# STM32WLE5_CM4 register map
File version: 1.0
CPU: CM4 r0p1, little endian, MPU, FPU, 4 interrupt priority bits
Registers are 32-bit, read-write, reset 0x0 unless marked. A register's access mark holds for its fields unless they carry their own. Offsets are from the block's base; [hi:lo] are bit positions.

## FLASH
Base 0x58004000
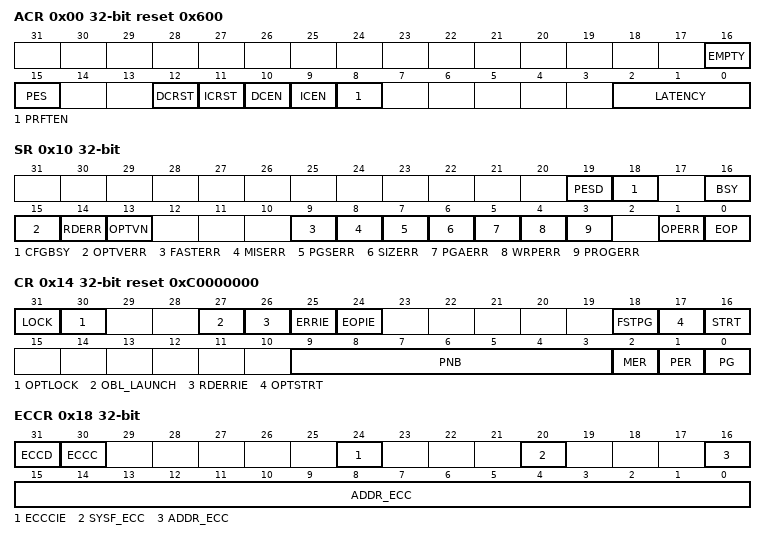
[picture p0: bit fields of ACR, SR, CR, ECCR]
0x00 ACR reset 0x600 — Access control register
  [16] EMPTY — Flash User area empty
  [15] PES — CPU1 programm erase suspend request
  [12] DCRST — Data cache reset
  [11] ICRST — Instruction cache reset
  [10] DCEN — Data cache enable
  [9] ICEN — Instruction cache enable
  [8] PRFTEN — Prefetch enable
  [2:0] LATENCY
0x08 KEYR wo — Flash key register
  [31:0] KEY
0x0C OPTKEYR wo — Option byte key register
  [31:0] OPTKEYR — Option byte key
0x10 SR access per field — Status register
  [19] PESD ro — Programming / erase operation suspended
  [18] CFGBSY ro — Programming or erase configuration busy
  [16] BSY ro — Busy
  [15] OPTVERR rw — Option validity error
  [14] RDERR rw — PCROP read error
  [13] OPTVN ro — User Option OPTIVAL indication
  [9] FASTERR rw — Fast programming error
  [8] MISERR rw — Fast programming data miss error
  [7] PGSERR rw — Programming sequence error
  [6] SIZERR rw — Size error
  [5] PGAERR rw — Programming alignment error
  [4] WRPERR rw — Write protected error
  [3] PROGERR rw — Programming error
  [1] OPERR rw — Operation error
  [0] EOP rw — End of operation
0x14 CR reset 0xC0000000 — Flash control register
  [31] LOCK — FLASH_CR Lock
  [30] OPTLOCK — Options Lock
  [27] OBL_LAUNCH — Force the option byte loading
  [26] RDERRIE — PCROP read error interrupt enable
  [25] ERRIE — Error interrupt enable
  [24] EOPIE — End of operation interrupt enable
  [18] FSTPG — Fast programming
  [17] OPTSTRT — Options modification start
  [16] STRT — Start
  [9:3] PNB — Page number
  [2] MER — Mass erase
  [1] PER — Page erase
  [0] PG — Programming
0x18 ECCR access per field — Flash ECC register
  [31] ECCD rw — ECC detection
  [30] ECCC rw — ECC correction
  [24] ECCCIE rw — ECC correction interrupt enable
  [20] SYSF_ECC ro — System Flash ECC fail
  [16:0] ADDR_ECC ro — ECC fail address
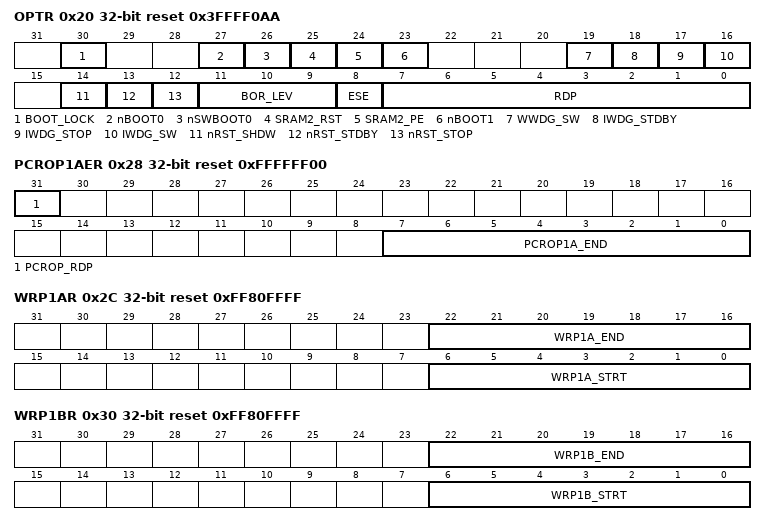
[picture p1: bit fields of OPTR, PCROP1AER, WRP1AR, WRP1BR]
0x20 OPTR reset 0x3FFFF0AA — Flash option register
  [30] BOOT_LOCK — CPU1 CM4 Unique Boot entry enable option bit
  [27] nBOOT0 — nBOOT0 option bit
  [26] nSWBOOT0 — Software BOOT0 selection
  [25] SRAM2_RST — SRAM2 Erase when system reset
  [24] SRAM2_PE — SRAM2 parity check enable
  [23] nBOOT1 — Boot configuration
  [19] WWDG_SW — Window watchdog selection
  [18] IWDG_STDBY — Independent watchdog counter freeze in Standby mode
  [17] IWDG_STOP — Independent watchdog counter freeze in Stop mode
  [16] IWDG_SW — Independent watchdog selection
  [14] nRST_SHDW
  [13] nRST_STDBY
  [12] nRST_STOP
  [11:9] BOR_LEV — BOR reset Level
  [8] ESE — System security enabled flag
  [7:0] RDP — Read protection level
0x24 PCROP1ASR ro reset 0xFFFFFFFF — Flash PCROP zone A Start address register
  [7:0] PCROP1A_STRT — PCROP1A area start offset
0x28 PCROP1AER reset 0xFFFFFF00 — Flash PCROP zone A End address register
  [31] PCROP_RDP — PCROP area preserved when RDP level decreased
  [7:0] PCROP1A_END — PCROP area end offset
0x2C WRP1AR reset 0xFF80FFFF — Flash WRP area A address register
  [22:16] WRP1A_END — Bank 1 WRP first area A end offset
  [6:0] WRP1A_STRT — Bank 1 WRP first area start offset
0x30 WRP1BR reset 0xFF80FFFF — Flash WRP area B address register
  [22:16] WRP1B_END — Bank 1 WRP second area B start offset
  [6:0] WRP1B_STRT — Bank 1 WRP second area B end offset
0x34 PCROP1BSR reset 0xFFFFFFFF — Flash PCROP zone B Start address register
  [7:0] PCROP1B_STRT — Bank 1 WRP second area B end offset
0x38 PCROP1BER reset 0xFFFFFF00 — Flash PCROP zone B End address register
  [7:0] PCROP1B_END — PCROP1B area end offset

## EXTI — External interrupt/event controller
Base 0x58000800
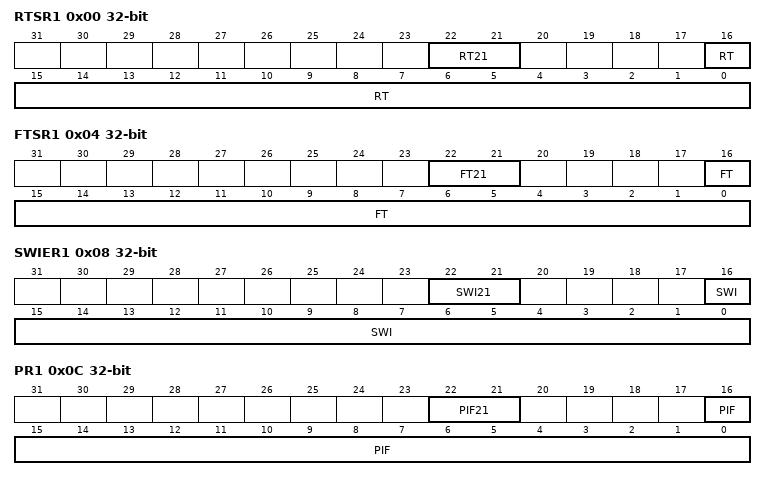
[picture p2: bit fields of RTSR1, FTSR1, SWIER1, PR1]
0x00 RTSR1 — rising trigger selection register
  [22:21] RT21 — Rising trigger event configuration bit of Configurable Event input
  [16:0] RT — Rising trigger event configuration bit of Configurable Event input
0x04 FTSR1 — falling trigger selection register
  [22:21] FT21 — Falling trigger event configuration bit of Configurable Event input
  [16:0] FT — Falling trigger event configuration bit of Configurable Event input
0x08 SWIER1 — software interrupt event register
  [22:21] SWI21 — Software interrupt on event
  [16:0] SWI — Software interrupt on event
0x0C PR1 — EXTI pending register
  [22:21] PIF21 — Configurable event inputs Pending bit
  [16:0] PIF — Configurable event inputs Pending bit
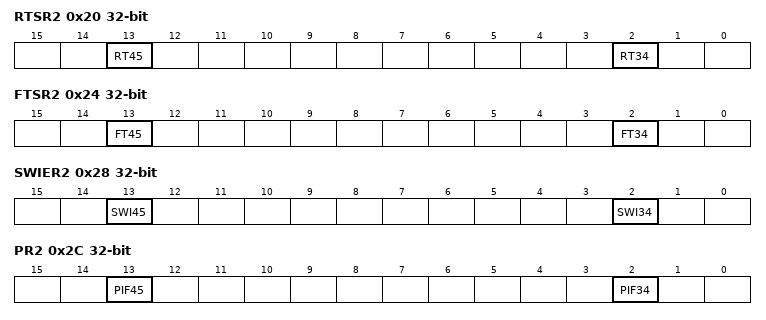
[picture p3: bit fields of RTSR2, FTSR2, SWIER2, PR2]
0x20 RTSR2 — rising trigger selection register
  [13] RT45 — Rising trigger event configuration bit of Configurable Event input
  [2] RT34 — Rising trigger event configuration bit of Configurable Event input
0x24 FTSR2 — falling trigger selection register
  [13] FT45 — Falling trigger event configuration bit of Configurable Event input
  [2] FT34 — Falling trigger event configuration bit of Configurable Event input
0x28 SWIER2 — software interrupt event register
  [13] SWI45 — Software interrupt on event 45
  [2] SWI34 — Software interrupt on event
0x2C PR2 — pending register
  [13] PIF45 — Configurable event inputs 45 Pending bit.
  [2] PIF34 — Configurable event inputs 33 Pending bit.
0x80 IMR1 — interrupt mask register
  [31:0] IM — wakeup with interrupt Mask on event input
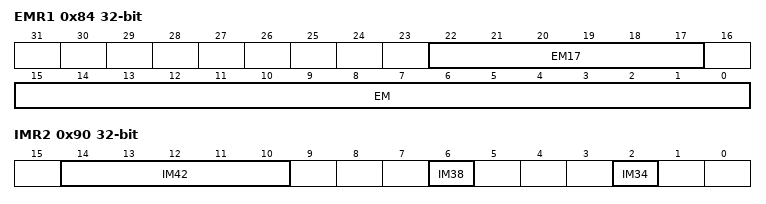
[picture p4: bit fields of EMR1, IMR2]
0x84 EMR1 — event mas register
  [22:17] EM17 — CPU(m) Wakeup with event generation Mask on Event input
  [15:0] EM — CPU(m) Wakeup with event generation Mask on Event input
0x90 IMR2 — interrupt mask register
  [14:10] IM42 — CPUm Wakeup with interrupt Mask on Event input
  [6] IM38 — CPUm Wakeup with interrupt Mask on Event input
  [2] IM34 — CPUm Wakeup with interrupt Mask on Event input
